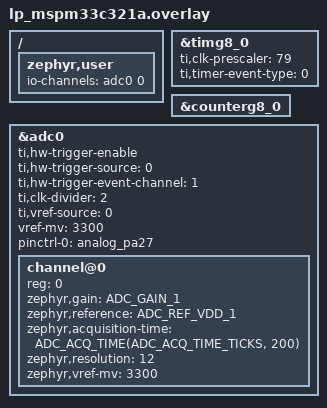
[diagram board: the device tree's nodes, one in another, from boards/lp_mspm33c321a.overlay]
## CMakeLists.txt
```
# SPDX-License-Identifier: Apache-2.0

cmake_minimum_required(VERSION 3.20.0)

find_package(Zephyr REQUIRED HINTS $ENV{ZEPHYR_BASE})
project(adc_timer_trigger)

target_sources(app PRIVATE
    src/main.c
    src/timer_event_config.c
)
```

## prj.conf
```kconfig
# ADC driver configuration
CONFIG_ADC=y

# Console configuration for output
CONFIG_CONSOLE=y
CONFIG_UART_CONSOLE=y

# Logging configuration
CONFIG_LOG=y
CONFIG_ADC_LOG_LEVEL_INF=y

# Counter/Timer driver (used for triggering)
CONFIG_COUNTER=y
```

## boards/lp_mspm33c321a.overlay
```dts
/*
 * Copyright (c) 2026 Texas Instruments
 *
 * SPDX-License-Identifier: Apache-2.0
 *
 * Board overlay for timer-triggered ADC sample on LP_MSPM33C321A.
 * Configures TIMG8_0 and ADC0 connected via event fabric channel 1.
 */

#include <zephyr/dt-bindings/adc/adc.h>

/ {
	zephyr,user {
		io-channels = <&adc0 0>;
	};
};

/*
 * Timer Configuration (Event Publisher)
 * - Clocked from MCLKBY2 (80 MHz) with prescaler 80 -> 1 MHz timer clock
 * - Configured by application for 1 kHz (1 ms) periodic triggering
 * - Publishes ti,timer-event-type events on event channel 1
 *
 * Available timer event types (ti,timer-event-type):
 *   0 = ZERO_EVENT  - Counter reaches zero (default, most common)
 *   1 = LOAD_EVENT  - Counter loaded with initial value
 *   2 = CC0_DN      - Capture/Compare 0 match (down counting)
 *   3 = CC0_UP      - Capture/Compare 0 match (up counting)
 *   4 = CC1_DN      - Capture/Compare 1 match (down counting)
 *   5 = CC1_UP      - Capture/Compare 1 match (up counting)
 */
&timg8_0 {
	status = "okay";
	ti,clk-prescaler = <79>;
	ti,timer-event-type = <0>;  /* ZERO_EVENT */
};

&counterg8_0 {
	status = "okay";
};

/*
 * ADC Configuration (Event Subscriber)
 * - Hardware-triggered via GEN_SUB_0 subscribed to event channel 1
 * - Channel 0 on PA27, 12-bit, VDDA reference (3.3V)
 */
&adc0 {
	status = "okay";

	ti,hw-trigger-enable;
	ti,hw-trigger-source = <0>;        /* GEN_SUB_0 */
	ti,hw-trigger-event-channel = <1>; /* Event channel 1 */

	ti,clk-divider = <2>;
	ti,vref-source = <0>;  /* VDDA */
	vref-mv = <3300>;

	pinctrl-0 = <&analog_pa27>;
	pinctrl-names = "default";

	#address-cells = <1>;
	#size-cells = <0>;

	channel@0 {
		reg = <0>;
		zephyr,gain = "ADC_GAIN_1";
		zephyr,reference = "ADC_REF_VDD_1";
		zephyr,acquisition-time = <ADC_ACQ_TIME(ADC_ACQ_TIME_TICKS, 200)>;
		zephyr,resolution = <12>;
		zephyr,vref-mv = <3300>;
	};
};

/*
 * Event Fabric Connection:
 * TIMG8_0 (timer event) -> Event Channel 1 -> HSADC GEN_SUB_0 (triggers ADC)
 *
 * Important: Event channel numbers must match between publisher and subscriber!
 */
```

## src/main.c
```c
/*
 * Copyright (c) 2026 Texas Instruments
 *
 * SPDX-License-Identifier: Apache-2.0
 */

/**
 * @file
 * @brief Timer-triggered ADC sample using MSPM33 event fabric
 *
 * Demonstrates hardware-triggered ADC conversions where a timer event
 * automatically triggers ADC sampling without CPU intervention.
 * Timer publishes events on channel 1, ADC subscribes to channel 1.
 */

#include <zephyr/kernel.h>
#include <zephyr/device.h>
#include <zephyr/drivers/adc.h>
#include <zephyr/sys/printk.h>
#include "timer_event_config.h"

/* ADC device from devicetree */
#define ADC_NODE DT_NODELABEL(adc0)
#define ADC_RESOLUTION 12
#define ADC_GAIN ADC_GAIN_1
#define ADC_REFERENCE ADC_REF_VDD_1
#define ADC_ACQUISITION_TIME ADC_ACQ_TIME(ADC_ACQ_TIME_TICKS, 200)
#define ADC_CHANNEL_ID 0

/* ADC channel configuration */
static const struct adc_channel_cfg adc_channel_cfg = {
	.gain = ADC_GAIN,
	.reference = ADC_REFERENCE,
	.acquisition_time = ADC_ACQUISITION_TIME,
	.channel_id = ADC_CHANNEL_ID,
};

/* ADC sequence buffer */
#define BUFFER_SIZE 1
static int16_t adc_sample_buffer[BUFFER_SIZE];

/* ADC sequence configuration */
static struct adc_sequence adc_sequence = {
	.buffer = adc_sample_buffer,
	.buffer_size = sizeof(adc_sample_buffer),
	.resolution = ADC_RESOLUTION,
};

/* Counter device from devicetree - configured to trigger ADC */
#define COUNTER_NODE DT_NODELABEL(counterg8_0)

/* Timer node for reading event type configuration */
#define TIMER_NODE DT_NODELABEL(timg8_0)

/* Timer event type from device tree (default to ZERO_EVENT if not specified) */
#define TIMER_EVENT_TYPE DT_PROP_OR(TIMER_NODE, ti_timer_event_type, 0)

/* Convert ADC raw value to millivolts (custom converter for this sample) */
static int32_t adc_convert_raw_to_millivolts(int16_t raw_value)
{
	/* For MSPM33 with 12-bit ADC and 3.3V reference:
	 * Voltage = (raw_value / 4095) * 3300 mV
	 */
	return (int32_t)((int64_t)raw_value * 3300 / 4095);
}

/* Get event type name for display */
static const char *get_event_name(enum timer_event_type event_type)
{
	switch (event_type) {
	case TIMER_EVENT_ZERO:
		return "ZERO_EVENT";
	case TIMER_EVENT_LOAD:
		return "LOAD_EVENT";
	case TIMER_EVENT_CC0_DN:
		return "CC0_DN";
	case TIMER_EVENT_CC0_UP:
		return "CC0_UP";
	case TIMER_EVENT_CC1_DN:
		return "CC1_DN";
	case TIMER_EVENT_CC1_UP:
		return "CC1_UP";
	default:
		return "UNKNOWN";
	}
}

int main(void)
{
	int err;
	uint32_t sample_count = 0;

	printk("\n=== MSPM33 Timer-Triggered ADC Sample ===\n");
	printk("This demonstrates hardware-triggered ADC conversions\n");
	printk("using the MSPM33 event fabric.\n\n");

	/* Get ADC device */
	const struct device *adc_dev = DEVICE_DT_GET(ADC_NODE);
	if (!device_is_ready(adc_dev)) {
		printk("ERROR: ADC device not ready\n");
		return -ENODEV;
	}
	printk("ADC device ready: %s\n", adc_dev->name);

	/* Get counter/timer device */
	const struct device *counter_dev = DEVICE_DT_GET(COUNTER_NODE);
	if (!device_is_ready(counter_dev)) {
		printk("ERROR: Counter device not ready\n");
		return -ENODEV;
	}
	printk("Counter device ready: %s\n", counter_dev->name);

	/* Configure ADC channel */
	err = adc_channel_setup(adc_dev, &adc_channel_cfg);
	if (err < 0) {
		printk("ERROR: Failed to configure ADC channel (err %d)\n", err);
		return err;
	}
	printk("ADC channel %d configured\n", ADC_CHANNEL_ID);

	/* Set up ADC sequence for this channel */
	adc_sequence.channels = BIT(ADC_CHANNEL_ID);

	/* Configure timer for event publishing with user-specified event type */
	enum timer_event_type event_type = (enum timer_event_type)TIMER_EVENT_TYPE;
	printk("Configuring timer for event publishing (event type: %d)...\n", event_type);
	err = configure_timer_event_publishing(counter_dev, event_type);
	if (err < 0) {
		printk("ERROR: Failed to configure timer event publishing (err %d)\n", err);
		return err;
	}

	/* Start timer for periodic ADC triggering at 1 kHz */
	printk("Starting timer at 1 kHz for ADC triggering...\n");
	err = start_timer_for_adc_trigger(counter_dev, 1000);
	if (err < 0) {
		printk("ERROR: Failed to start timer (err %d)\n", err);
		return err;
	}
	printk("Timer started\n");

	printk("\nConfiguration:\n");
	printk("  - Timer: %s\n", counter_dev->name);
	printk("  - Timer frequency: 1 kHz (1 ms period)\n");
	printk("  - Timer event type: %s\n", get_event_name(event_type));
	printk("  - Event channel: 1\n");
	printk("  - ADC channel: %d (PA27)\n", ADC_CHANNEL_ID);
	printk("  - ADC resolution: %d bits\n", ADC_RESOLUTION);
	printk("  - Reference voltage: VDDA (3.3V)\n");
	printk("  - Hardware trigger: Enabled (GEN_SUB_0)\n");
	printk("\nHardware trigger path:\n");
	printk("  Timer %s -> Event Channel 1 -> ADC GEN_SUB_0 -> Conversion\n",
	       get_event_name(event_type));

	printk("\nStarting periodic ADC sampling (timer-triggered)...\n");
	printk("Timer triggers ADC every 1 ms. Reading samples every 1 second.\n\n");

	while (1) {
		/* Start ADC read - waits for next hardware trigger */
		err = adc_read(adc_dev, &adc_sequence);
		if (err < 0) {
			printk("ERROR: ADC read failed (err %d)\n", err);
			k_sleep(K_MSEC(1000));
			continue;
		}

		/* Get the raw ADC value */
		int16_t raw_value = adc_sample_buffer[0];

		/* Convert to millivolts */
		int32_t millivolts = adc_convert_raw_to_millivolts(raw_value);

		/* Print result */
		sample_count++;
		printk("[%6u] ADC CH%d: Raw=%4d (0x%03X), Voltage=%4d mV\n",
		       sample_count, ADC_CHANNEL_ID, raw_value, raw_value & 0xFFF, millivolts);

		/* Wait 1 second before next reading (timer continues triggering at 1 kHz) */
		k_sleep(K_MSEC(1000));
	}

	return 0;
}
```

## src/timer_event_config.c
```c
/*
 * Copyright (c) 2026 Texas Instruments
 *
 * SPDX-License-Identifier: Apache-2.0
 */

/**
 * @file
 * @brief Timer event publishing configuration for ADC hardware triggering
 *
 * Configures MSPM33 timer to publish events on the event fabric for
 * triggering ADC conversions. This is a sample-specific configuration;
 * future work may integrate this into the timer driver.
 */

#include <zephyr/kernel.h>
#include <zephyr/device.h>
#include <zephyr/drivers/counter.h>
#include <zephyr/sys/printk.h>
#include "timer_event_config.h"

/* Driverlib includes for direct hardware configuration */
#include <ti/driverlib/dl_timera.h>
#include <soc.h>  /* For TIMG8_0 base address */

/* TIMG8_0 is already defined in device header */
#define TIMG8_0 ((GPTIMER_Regs *)TIMG8_0_BASE)

/* Event channel configuration */
#define ADC_TRIGGER_EVENT_CHANNEL 1  /* Must match ADC overlay config */

/* Map timer event type enum to driverlib event mask */
static uint32_t map_event_type(enum timer_event_type event_type)
{
	switch (event_type) {
	case TIMER_EVENT_ZERO:
		return DL_TIMERA_EVENT_ZERO_EVENT;
	case TIMER_EVENT_LOAD:
		return DL_TIMERA_EVENT_LOAD_EVENT;
	case TIMER_EVENT_CC0_DN:
		return DL_TIMERA_EVENT_CC0_DN_EVENT;
	case TIMER_EVENT_CC0_UP:
		return DL_TIMERA_EVENT_CC0_UP_EVENT;
	case TIMER_EVENT_CC1_DN:
		return DL_TIMERA_EVENT_CC1_DN_EVENT;
	case TIMER_EVENT_CC1_UP:
		return DL_TIMERA_EVENT_CC1_UP_EVENT;
	default:
		return DL_TIMERA_EVENT_ZERO_EVENT; /* Default to ZERO */
	}
}

/* Get event type name string for logging */
static const char *get_event_type_name(enum timer_event_type event_type)
{
	switch (event_type) {
	case TIMER_EVENT_ZERO:
		return "ZERO_EVENT";
	case TIMER_EVENT_LOAD:
		return "LOAD_EVENT";
	case TIMER_EVENT_CC0_DN:
		return "CC0_DN_EVENT";
	case TIMER_EVENT_CC0_UP:
		return "CC0_UP_EVENT";
	case TIMER_EVENT_CC1_DN:
		return "CC1_DN_EVENT";
	case TIMER_EVENT_CC1_UP:
		return "CC1_UP_EVENT";
	default:
		return "UNKNOWN";
	}
}

/**
 * @brief Configure timer to publish events for ADC triggering
 *
 * Enables the specified timer event type and configures it to publish
 * on event channel 1 for ADC hardware triggering.
 *
 * @param counter_dev Counter device pointer
 * @param event_type Timer event type to publish
 * @return 0 on success, negative error code on failure
 */
int configure_timer_event_publishing(const struct device *counter_dev,
				     enum timer_event_type event_type)
{
	if (!device_is_ready(counter_dev)) {
		return -ENODEV;
	}

	/* Map enum to driverlib event mask */
	uint32_t event_mask = map_event_type(event_type);

	/* Configure timer to publish specified event on event route 1 */
	DL_TimerA_enableEvent(TIMG8_0, DL_TIMERA_EVENT_ROUTE_1, event_mask);

	/* Set publisher channel ID to 1 (must match ADC subscriber channel) */
	DL_TimerA_setPublisherChanID(TIMG8_0, DL_TIMERA_PUBLISHER_INDEX_0,
				     ADC_TRIGGER_EVENT_CHANNEL);

	printk("Timer event publishing configured: %s\n", get_event_type_name(event_type));

	return 0;
}

/**
 * @brief Start timer for periodic ADC triggering
 *
 * Starts the timer in periodic mode at the specified frequency.
 * Timer event publishing must be configured first.
 *
 * @param counter_dev Counter device pointer
 * @param frequency_hz Trigger frequency in Hz
 * @return 0 on success, negative error code on failure
 */
int start_timer_for_adc_trigger(const struct device *counter_dev, uint32_t frequency_hz)
{
	if (!device_is_ready(counter_dev)) {
		return -ENODEV;
	}

	/* Get timer frequency from counter API */
	uint32_t timer_freq = counter_get_frequency(counter_dev);

	/* Calculate period for desired frequency */
	uint32_t period_ticks = timer_freq / frequency_hz;

	/* Start counter first */
	int err = counter_start(counter_dev);
	if (err < 0) {
		return err;
	}

	/* Get current counter value */
	uint32_t current_ticks = 0;
	err = counter_get_value(counter_dev, &current_ticks);
	if (err < 0) {
		return err;
	}

	/* Calculate alarm tick (current + period) for immediate first trigger */
	uint32_t alarm_ticks = current_ticks + period_ticks;

	/* Configure counter alarm for periodic triggering */
	struct counter_alarm_cfg alarm_cfg = {
		.flags = COUNTER_ALARM_CFG_ABSOLUTE,
		.ticks = alarm_ticks,
		.callback = NULL,  /* No callback needed, hardware trigger only */
		.user_data = NULL,
	};

	/* Set alarm to generate events */
	err = counter_set_channel_alarm(counter_dev, 0, &alarm_cfg);
	if (err < 0) {
		return err;
	}

	return 0;
}
```

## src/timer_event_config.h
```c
/*
 * Copyright (c) 2026 Texas Instruments
 *
 * SPDX-License-Identifier: Apache-2.0
 */

#ifndef TIMER_EVENT_CONFIG_H_
#define TIMER_EVENT_CONFIG_H_

#include <zephyr/device.h>
#include <stdint.h>

/* Timer event types for ADC triggering via event fabric */
enum timer_event_type {
	TIMER_EVENT_ZERO = 0,   /**< Counter reaches zero (most common) */
	TIMER_EVENT_LOAD = 1,   /**< Counter loaded with initial value */
	TIMER_EVENT_CC0_DN = 2, /**< Capture/Compare 0 match (down counting) */
	TIMER_EVENT_CC0_UP = 3, /**< Capture/Compare 0 match (up counting) */
	TIMER_EVENT_CC1_DN = 4, /**< Capture/Compare 1 match (down counting) */
	TIMER_EVENT_CC1_UP = 5, /**< Capture/Compare 1 match (up counting) */
};

/** Configure timer to publish events for ADC triggering */
int configure_timer_event_publishing(const struct device *counter_dev,
				     enum timer_event_type event_type);

/** Start timer for periodic ADC triggering */
int start_timer_for_adc_trigger(const struct device *counter_dev, uint32_t frequency_hz);

#endif /* TIMER_EVENT_CONFIG_H_ */
```
